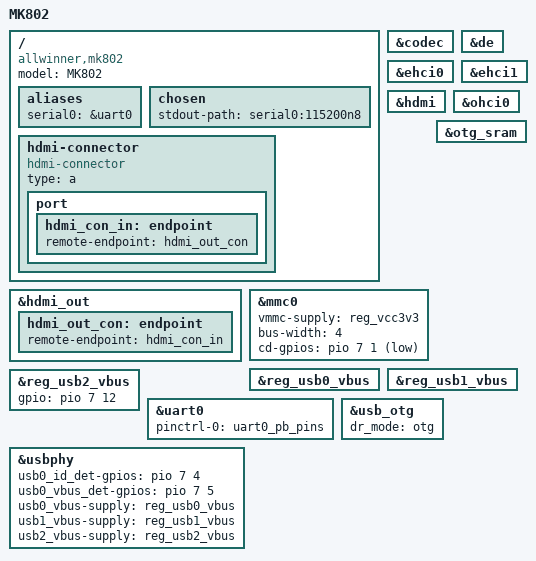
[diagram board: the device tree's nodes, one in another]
/dts-v1/;
#include "sun4i-a10.dtsi"
#include "sunxi-common-regulators.dtsi"
#include <dt-bindings/gpio/gpio.h>
/ {
	model = "MK802";
	compatible = "allwinner,mk802", "allwinner,sun4i-a10";
	aliases {
		serial0 = &uart0;
	};
	chosen {
		stdout-path = "serial0:115200n8";
	};
	hdmi-connector {
		compatible = "hdmi-connector";
		type = "a";
		port {
			hdmi_con_in: endpoint {
				remote-endpoint = <&hdmi_out_con>;
			};
		};
	};
};
&codec {
	status = "okay";
};
&de {
	status = "okay";
};
&ehci0 {
	status = "okay";
};
&ehci1 {
	status = "okay";
};
&hdmi {
	status = "okay";
};
&hdmi_out {
	hdmi_out_con: endpoint {
		remote-endpoint = <&hdmi_con_in>;
	};
};
&mmc0 {
	vmmc-supply = <&reg_vcc3v3>;
	bus-width = <4>;
	cd-gpios = <&pio 7 1 GPIO_ACTIVE_LOW>;  
	status = "okay";
};
&ohci0 {
	status = "okay";
};
&otg_sram {
	status = "okay";
};
&reg_usb0_vbus {
	status = "okay";
};
&reg_usb1_vbus {
	status = "okay";
};
&reg_usb2_vbus {
	gpio = <&pio 7 12 GPIO_ACTIVE_HIGH>;  
	status = "okay";
};
&uart0 {
	pinctrl-names = "default";
	pinctrl-0 = <&uart0_pb_pins>;
	status = "okay";
};
&usb_otg {
	dr_mode = "otg";
	status = "okay";
};
&usbphy {
	usb0_id_det-gpios = <&pio 7 4 GPIO_ACTIVE_HIGH>;  
	usb0_vbus_det-gpios = <&pio 7 5 GPIO_ACTIVE_HIGH>;  
	usb0_vbus-supply = <&reg_usb0_vbus>;
	usb1_vbus-supply = <&reg_usb1_vbus>;
	usb2_vbus-supply = <&reg_usb2_vbus>;
	status = "okay";
};
